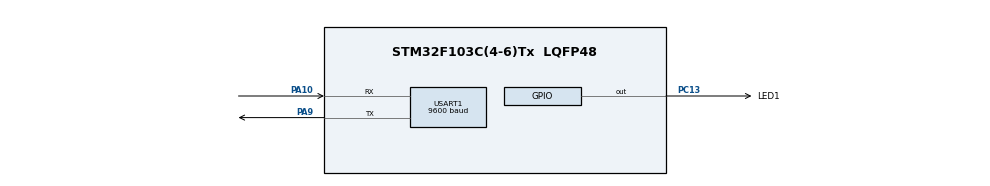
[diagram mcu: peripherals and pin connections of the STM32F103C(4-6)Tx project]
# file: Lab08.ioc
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Dma.Request0=USART1_RX
Dma.Request1=USART1_TX
Dma.USART1_RX.0.Direction=DMA_PERIPH_TO_MEMORY
Dma.USART1_RX.0.Instance=DMA1_Channel5
Dma.USART1_RX.0.MemDataAlignment=DMA_MDATAALIGN_BYTE
Dma.USART1_RX.0.MemInc=DMA_MINC_ENABLE
Dma.USART1_RX.0.Mode=DMA_NORMAL
Dma.USART1_RX.0.PeriphDataAlignment=DMA_PDATAALIGN_BYTE
Dma.USART1_RX.0.PeriphInc=DMA_PINC_DISABLE
Dma.USART1_RX.0.Priority=DMA_PRIORITY_LOW
Dma.USART1_TX.1.Direction=DMA_MEMORY_TO_PERIPH
Dma.USART1_TX.1.Instance=DMA1_Channel4
Dma.USART1_TX.1.MemDataAlignment=DMA_MDATAALIGN_BYTE
Dma.USART1_TX.1.MemInc=DMA_MINC_ENABLE
Dma.USART1_TX.1.Mode=DMA_NORMAL
Dma.USART1_TX.1.PeriphDataAlignment=DMA_PDATAALIGN_BYTE
Dma.USART1_TX.1.PeriphInc=DMA_PINC_DISABLE
Dma.USART1_TX.1.Priority=DMA_PRIORITY_LOW
Mcu.Family=STM32F1
Mcu.Name=STM32F103C(4-6)Tx
Mcu.Package=LQFP48
NVIC.DMA1_Channel4_IRQn=true\:0\:0\:false\:true\:true\:3\:false\:true
NVIC.DMA1_Channel5_IRQn=true\:0\:0\:false\:true\:true\:2\:false\:true
NVIC.PriorityGroup=NVIC_PRIORITYGROUP_4
NVIC.USART1_IRQn=true\:0\:0\:false\:true\:true\:1\:true\:true
PA10.Mode=Asynchronous
PA10.Signal=USART1_RX
PA9.Mode=Asynchronous
PA9.Signal=USART1_TX
PC13-TAMPER-RTC.GPIO_Label=LED1
PC13-TAMPER-RTC.Signal=GPIO_Output
ProjectManager.HeapSize=0x200
ProjectManager.StackSize=0x400
ProjectManager.TargetToolchain=STM32CubeIDE
RCC.APB1Freq_Value=8000000
RCC.APB2Freq_Value=8000000
USART1.BaudRate=9600
USART1.VirtualMode=VM_ASYNC
VP_SYS_VS_ND.Mode=No_Debug
board=custom

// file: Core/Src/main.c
/* USER CODE BEGIN Header */
/**
  ******************************************************************************
  * @file           : main.c
  * @brief          : Main program body
  ******************************************************************************
  * @attention
  *
  * <h2><center>&copy; Copyright (c) 2021 STMicroelectronics.
  * All rights reserved.</center></h2>
  *
  * This software component is licensed by ST under BSD 3-Clause license,
  * the "License"; You may not use this file except in compliance with the
  * License. You may obtain a copy of the License at:
  *                        opensource.org/licenses/BSD-3-Clause
  *
  ******************************************************************************
  */
/* USER CODE END Header */
#include "main.h"

/* USER CODE BEGIN Includes */
#include <stdbool.h>
/* USER CODE END Includes */

UART_HandleTypeDef huart1;
DMA_HandleTypeDef hdma_usart1_rx;
DMA_HandleTypeDef hdma_usart1_tx;

/* USER CODE BEGIN PV */
uint8_t dma_buffer[2000];
volatile bool toggle = 0;
bool state = false;
uint8_t UART1_rxBuffer[1] = {0};
/* USER CODE END PV */

void SystemClock_Config(void);
static void MX_GPIO_Init(void);
static void MX_DMA_Init(void);
static void MX_USART1_UART_Init(void);
static void MX_NVIC_Init(void);

int main(void)
{

  /* MCU Configuration--------------------------------------------------------*/

  /* Reset of all peripherals, Initializes the Flash interface and the Systick. */
  HAL_Init();

  /* Configure the system clock */
  SystemClock_Config();

  /* Initialize all configured peripherals */
  MX_GPIO_Init();
  MX_DMA_Init();
  MX_USART1_UART_Init();

  /* Initialize interrupts */
  MX_NVIC_Init();
  /* USER CODE BEGIN 2 */
  uint16_t i;
  for(i = 0; i < 1998; i++)
  {
    dma_buffer[i] = 'x';
  }
  dma_buffer[1998] = '\r';
  dma_buffer[1999] = '\n';

  /* USER CODE END 2 */

  /* Infinite loop */
  /* USER CODE BEGIN WHILE */
    HAL_UART_Transmit_IT(&huart1, (uint8_t *) "Welcome\n\r\tPress 0 or 1\n\r", sizeof("Welcome\n\r\tPress 0 or 1\n\r"));
    HAL_UART_Receive_DMA(&huart1, UART1_rxBuffer, 1);
    //HAL_UART_Transmit_DMA(&huart1, dma_buffer, 2000);

  while (1)
  {
    /* USER CODE END WHILE */
		while(state)
		{
			HAL_UART_Transmit_DMA(&huart1, dma_buffer, 2000);
		}
  }
}

void SystemClock_Config(void)
{
  RCC_OscInitTypeDef RCC_OscInitStruct = {0};
  RCC_ClkInitTypeDef RCC_ClkInitStruct = {0};

  /** Initializes the RCC Oscillators according to the specified parameters
  * in the RCC_OscInitTypeDef structure.
  */
  RCC_OscInitStruct.OscillatorType = RCC_OSCILLATORTYPE_HSI;
  RCC_OscInitStruct.HSIState = RCC_HSI_ON;
  RCC_OscInitStruct.HSICalibrationValue = RCC_HSICALIBRATION_DEFAULT;
  RCC_OscInitStruct.PLL.PLLState = RCC_PLL_NONE;
  if (HAL_RCC_OscConfig(&RCC_OscInitStruct) != HAL_OK)
  {
    Error_Handler();
  }
  /** Initializes the CPU, AHB and APB buses clocks
  */
  RCC_ClkInitStruct.ClockType = RCC_CLOCKTYPE_HCLK|RCC_CLOCKTYPE_SYSCLK
                              |RCC_CLOCKTYPE_PCLK1|RCC_CLOCKTYPE_PCLK2;
  RCC_ClkInitStruct.SYSCLKSource = RCC_SYSCLKSOURCE_HSI;
  RCC_ClkInitStruct.AHBCLKDivider = RCC_SYSCLK_DIV1;
  RCC_ClkInitStruct.APB1CLKDivider = RCC_HCLK_DIV1;
  RCC_ClkInitStruct.APB2CLKDivider = RCC_HCLK_DIV1;

  if (HAL_RCC_ClockConfig(&RCC_ClkInitStruct, FLASH_LATENCY_0) != HAL_OK)
  {
    Error_Handler();
  }
}

/**
  * @brief NVIC Configuration.
  * @retval None
  */
static void MX_NVIC_Init(void)
{
  /* USART1_IRQn interrupt configuration */
  HAL_NVIC_SetPriority(USART1_IRQn, 0, 0);
  HAL_NVIC_EnableIRQ(USART1_IRQn);
  /* DMA1_Channel5_IRQn interrupt configuration */
  HAL_NVIC_SetPriority(DMA1_Channel5_IRQn, 0, 0);
  HAL_NVIC_EnableIRQ(DMA1_Channel5_IRQn);
  /* DMA1_Channel4_IRQn interrupt configuration */
  HAL_NVIC_SetPriority(DMA1_Channel4_IRQn, 0, 0);
  HAL_NVIC_EnableIRQ(DMA1_Channel4_IRQn);
}

static void MX_USART1_UART_Init(void)
{

  huart1.Instance = USART1;
  huart1.Init.BaudRate = 9600;
  huart1.Init.WordLength = UART_WORDLENGTH_8B;
  huart1.Init.StopBits = UART_STOPBITS_1;
  huart1.Init.Parity = UART_PARITY_NONE;
  huart1.Init.Mode = UART_MODE_TX_RX;
  huart1.Init.HwFlowCtl = UART_HWCONTROL_NONE;
  huart1.Init.OverSampling = UART_OVERSAMPLING_16;
  if (HAL_UART_Init(&huart1) != HAL_OK)
  {
    Error_Handler();
  }

}

static void MX_DMA_Init(void)
{

  /* DMA controller clock enable */
  __HAL_RCC_DMA1_CLK_ENABLE();

}

static void MX_GPIO_Init(void)
{
  GPIO_InitTypeDef GPIO_InitStruct = {0};

  /* GPIO Ports Clock Enable */
  __HAL_RCC_GPIOC_CLK_ENABLE();
  __HAL_RCC_GPIOA_CLK_ENABLE();

  /*Configure GPIO pin Output Level */
  HAL_GPIO_WritePin(LED1_GPIO_Port, LED1_Pin, GPIO_PIN_RESET);

  /*Configure GPIO pin : LED1_Pin */
  GPIO_InitStruct.Pin = LED1_Pin;
  GPIO_InitStruct.Mode = GPIO_MODE_OUTPUT_PP;
  GPIO_InitStruct.Pull = GPIO_NOPULL;
  GPIO_InitStruct.Speed = GPIO_SPEED_FREQ_LOW;
  HAL_GPIO_Init(LED1_GPIO_Port, &GPIO_InitStruct);

}

/* USER CODE BEGIN 4 */
void HAL_UART_RxCpltCallback(UART_HandleTypeDef *huart)
{
	if (UART1_rxBuffer[0] == '0')
	{
		HAL_UART_AbortTransmit(&huart1);
		state = false;
		HAL_UART_Transmit(&huart1, (uint8_t *) "\n\r", 2, 100);
		HAL_UART_Transmit(&huart1, UART1_rxBuffer, 1, 100);
		HAL_UART_Transmit(&huart1, (uint8_t*) "\n\rStop\n\r", sizeof("\n\rStop\n\r"), 100);
	}
	if (UART1_rxBuffer[0] == '1')
		{
			state = true;
			HAL_UART_Transmit(&huart1, (uint8_t *) "\n\r", 2, 100);
			HAL_UART_Transmit(&huart1, UART1_rxBuffer, 1, 100);
			HAL_UART_Transmit(&huart1, (uint8_t*) "\n\rStart\n\r", sizeof("\n\rStart\n\r"), 100);

		}

		if (UART1_rxBuffer[0] != '0' && UART1_rxBuffer[0] != '1')
		{
			HAL_UART_Transmit(&huart1, (uint8_t*) "\n\rPress 0 or 1\n\r", sizeof("\n\rPress 0 or 1\n\r"), 100);
		}

		HAL_UART_Receive_DMA(&huart1, UART1_rxBuffer, 1);
	}
void HAL_UART_TxCpltCallback(UART_HandleTypeDef *huart)
{
  uint16_t i;
  toggle = !toggle;

  for(i = 1000; i < 1998; i++)
  {
    if(toggle)
      dma_buffer[i] = '&';
    else
      dma_buffer[i] = 'z';
  }

  dma_buffer[1998] = '\r';
  dma_buffer[1999] = '\n';

  //HAL_UART_Transmit_DMA(&huart1, dma_buffer, 2000);
  HAL_GPIO_TogglePin(LED1_GPIO_Port, LED1_Pin);
}

void HAL_UART_TxHalfCpltCallback(UART_HandleTypeDef *huart)
{
  uint16_t i;

  for(i = 0; i < 1000; i++)
  {
    if(toggle)
      dma_buffer[i] = 'y';
    else
      dma_buffer[i] = '|';
  }
}

/* USER CODE END 4 */

void Error_Handler(void)
{
  __disable_irq();
  while (1)
  {
  }
}

/************************ (C) COPYRIGHT STMicroelectronics *****END OF FILE****/
